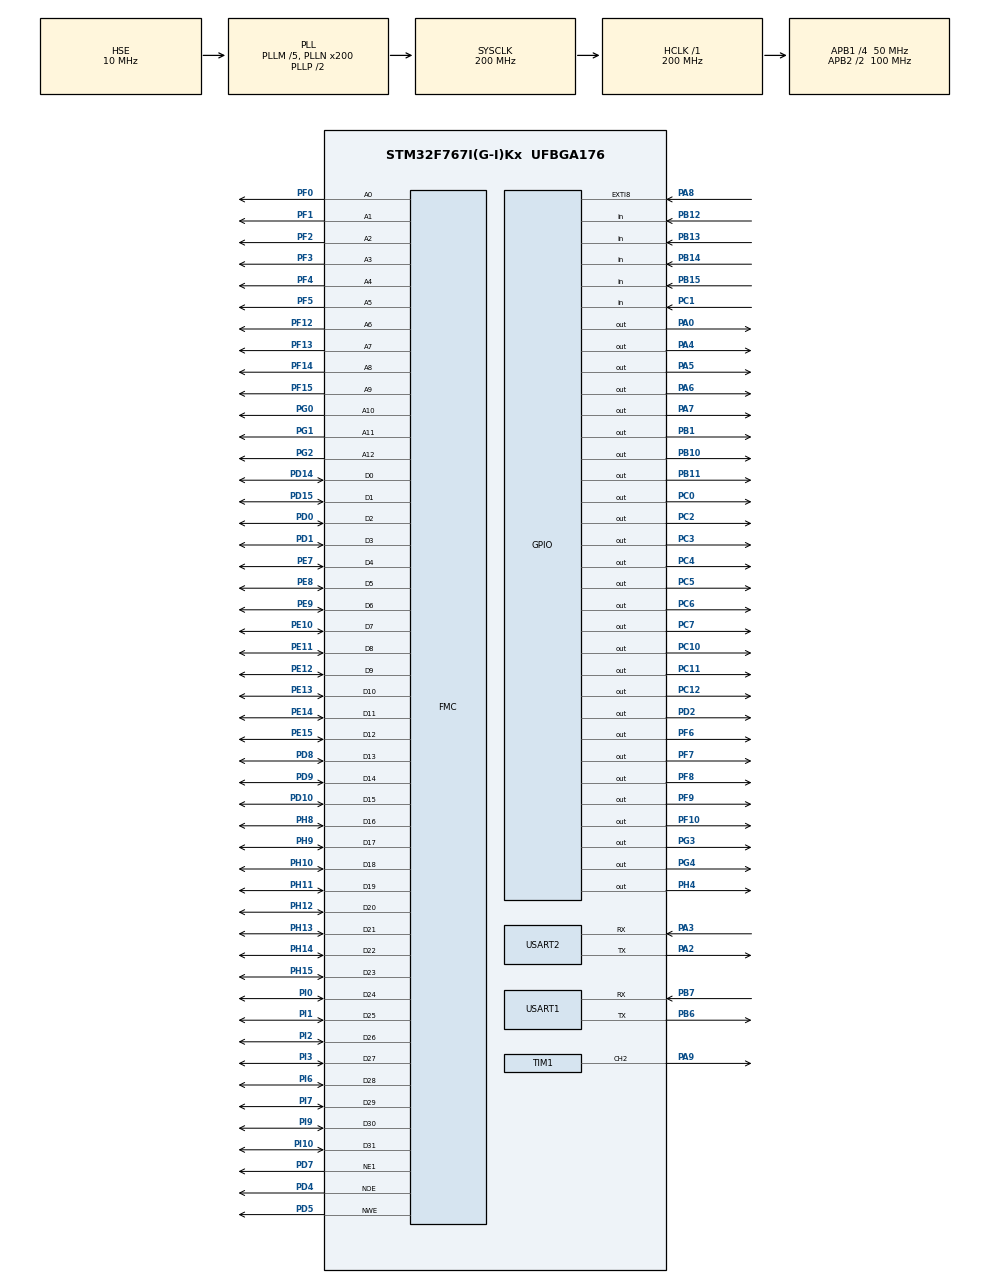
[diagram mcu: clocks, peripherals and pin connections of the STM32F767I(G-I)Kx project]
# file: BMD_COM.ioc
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CORTEX_M7.CPU_DCache=Disabled
CORTEX_M7.CPU_ICache=Enabled
Dma.Request0=USART2_RX
Dma.Request1=USART1_TX
Dma.Request2=USART1_RX
Dma.USART1_RX.2.Direction=DMA_PERIPH_TO_MEMORY
Dma.USART1_RX.2.FIFOMode=DMA_FIFOMODE_DISABLE
Dma.USART1_RX.2.Instance=DMA2_Stream2
Dma.USART1_RX.2.MemDataAlignment=DMA_MDATAALIGN_BYTE
Dma.USART1_RX.2.MemInc=DMA_MINC_ENABLE
Dma.USART1_RX.2.Mode=DMA_CIRCULAR
Dma.USART1_RX.2.PeriphDataAlignment=DMA_PDATAALIGN_BYTE
Dma.USART1_RX.2.PeriphInc=DMA_PINC_DISABLE
Dma.USART1_RX.2.Priority=DMA_PRIORITY_VERY_HIGH
Dma.USART1_TX.1.Direction=DMA_MEMORY_TO_PERIPH
Dma.USART1_TX.1.FIFOMode=DMA_FIFOMODE_DISABLE
Dma.USART1_TX.1.Instance=DMA2_Stream7
Dma.USART1_TX.1.MemDataAlignment=DMA_MDATAALIGN_BYTE
Dma.USART1_TX.1.MemInc=DMA_MINC_ENABLE
Dma.USART1_TX.1.Mode=DMA_NORMAL
Dma.USART1_TX.1.PeriphDataAlignment=DMA_PDATAALIGN_BYTE
Dma.USART1_TX.1.PeriphInc=DMA_PINC_DISABLE
Dma.USART1_TX.1.Priority=DMA_PRIORITY_LOW
Dma.USART2_RX.0.Direction=DMA_PERIPH_TO_MEMORY
Dma.USART2_RX.0.FIFOMode=DMA_FIFOMODE_DISABLE
Dma.USART2_RX.0.Instance=DMA1_Stream5
Dma.USART2_RX.0.MemDataAlignment=DMA_MDATAALIGN_BYTE
Dma.USART2_RX.0.MemInc=DMA_MINC_ENABLE
Dma.USART2_RX.0.Mode=DMA_CIRCULAR
Dma.USART2_RX.0.PeriphDataAlignment=DMA_PDATAALIGN_BYTE
Dma.USART2_RX.0.PeriphInc=DMA_PINC_DISABLE
Dma.USART2_RX.0.Priority=DMA_PRIORITY_HIGH
FMC.AddressSetupTime1=2
FMC.BusTurnAroundDuration1=2
FMC.DataSetupTime1=2
Mcu.Family=STM32F7
Mcu.Name=STM32F767I(G-I)Kx
Mcu.Package=UFBGA176
Mcu.UserConstants=USART1_BaudRate,921600;USART2_BaudRate,921600
NVIC.DMA1_Stream5_IRQn=true\:3\:0\:true\:true\:true\:5\:false\:true
NVIC.DMA2_Stream2_IRQn=true\:1\:0\:true\:true\:true\:6\:false\:true
NVIC.DMA2_Stream7_IRQn=true\:2\:0\:true\:true\:true\:2\:true\:true
NVIC.EXTI9_5_IRQn=true\:5\:0\:true\:true\:true\:3\:true\:true
NVIC.PriorityGroup=NVIC_PRIORITYGROUP_4
NVIC.TIM3_IRQn=true\:5\:0\:true\:true\:true\:4\:true\:true
NVIC.TIM6_DAC_IRQn=true\:4\:0\:true\:true\:true\:1\:true\:true
NVIC.USART1_IRQn=true\:0\:0\:true\:true\:true\:7\:true\:true
NVIC.USART2_IRQn=true\:6\:0\:true\:true\:true\:8\:true\:true
PA0/WKUP.GPIO_PuPd=GPIO_PULLUP
PA0/WKUP.Signal=GPIO_Output
PA2.GPIO_ModeDefaultPP=GPIO_MODE_AF_OD
PA2.Mode=Asynchronous
PA2.Signal=USART2_TX
PA3.GPIO_ModeDefaultPP=GPIO_MODE_AF_PP
PA3.Mode=Asynchronous
PA3.Signal=USART2_RX
PA4.GPIO_PuPd=GPIO_PULLUP
PA4.Signal=GPIO_Output
PA5.GPIO_PuPd=GPIO_PULLUP
PA5.Signal=GPIO_Output
PA6.GPIO_PuPd=GPIO_PULLUP
PA6.Signal=GPIO_Output
PA7.GPIO_PuPd=GPIO_PULLUP
PA7.Signal=GPIO_Output
PA8.GPIO_ModeDefaultEXTI=GPIO_MODE_IT_FALLING
PA8.GPIO_PuPd=GPIO_PULLUP
PA8.Signal=GPXTI8
PA9.Signal=S_TIM1_CH2
PB1.GPIO_PuPd=GPIO_PULLUP
PB1.Signal=GPIO_Output
PB10.GPIO_PuPd=GPIO_PULLUP
PB10.Signal=GPIO_Output
PB11.GPIO_PuPd=GPIO_PULLUP
PB11.Signal=GPIO_Output
PB12.GPIO_Mode=GPIO_MODE_INPUT
PB12.GPIO_PuPd=GPIO_PULLUP
PB12.Signal=GPIO_Input
PB13.GPIO_Mode=GPIO_MODE_INPUT
PB13.GPIO_PuPd=GPIO_PULLUP
PB13.Signal=GPIO_Input
PB14.GPIO_Mode=GPIO_MODE_INPUT
PB14.GPIO_PuPd=GPIO_PULLUP
PB14.Signal=GPIO_Input
PB15.GPIO_Mode=GPIO_MODE_INPUT
PB15.GPIO_PuPd=GPIO_PULLUP
PB15.Signal=GPIO_Input
PB6.Mode=Asynchronous
PB6.Signal=USART1_TX
PB7.Mode=Asynchronous
PB7.Signal=USART1_RX
PC0.GPIO_PuPd=GPIO_PULLUP
PC0.Signal=GPIO_Output
PC1.Signal=GPIO_Input
PC10.GPIO_PuPd=GPIO_PULLUP
PC10.Signal=GPIO_Output
PC11.GPIO_PuPd=GPIO_PULLUP
PC11.Signal=GPIO_Output
PC12.GPIO_PuPd=GPIO_PULLUP
PC12.Signal=GPIO_Output
PC2.GPIO_PuPd=GPIO_PULLUP
PC2.Signal=GPIO_Output
PC3.GPIO_PuPd=GPIO_PULLUP
PC3.Signal=GPIO_Output
PC4.GPIO_PuPd=GPIO_PULLUP
PC4.Signal=GPIO_Output
PC5.GPIO_PuPd=GPIO_PULLUP
PC5.Signal=GPIO_Output
PC6.GPIO_PuPd=GPIO_PULLUP
PC6.Signal=GPIO_Output
PC7.GPIO_PuPd=GPIO_PULLUP
PC7.Signal=GPIO_Output
PD0.Signal=FMC_D2_DA2
PD1.Signal=FMC_D3_DA3
PD10.Signal=FMC_D15_DA15
PD14.Signal=FMC_D0_DA0
PD15.Signal=FMC_D1_DA1
PD2.GPIO_PuPd=GPIO_PULLUP
PD2.Signal=GPIO_Output
PD4.Signal=FMC_NOE
PD5.Signal=FMC_NWE
PD7.Mode=NorPsramChipSelect1_1
PD7.Signal=FMC_NE1
PD8.Signal=FMC_D13_DA13
PD9.Signal=FMC_D14_DA14
PE10.Signal=FMC_D7_DA7
PE11.Signal=FMC_D8_DA8
PE12.Signal=FMC_D9_DA9
PE13.Signal=FMC_D10_DA10
PE14.Signal=FMC_D11_DA11
PE15.Signal=FMC_D12_DA12
PE7.Signal=FMC_D4_DA4
PE8.Signal=FMC_D5_DA5
PE9.Signal=FMC_D6_DA6
PF0.Signal=FMC_A0
PF1.Signal=FMC_A1
PF10.GPIO_PuPd=GPIO_PULLUP
PF10.Signal=GPIO_Output
PF12.Signal=FMC_A6
PF13.Signal=FMC_A7
PF14.Signal=FMC_A8
PF15.Signal=FMC_A9
PF2.Signal=FMC_A2
PF3.Signal=FMC_A3
PF4.Signal=FMC_A4
PF5.Signal=FMC_A5
PF6.GPIO_PuPd=GPIO_PULLUP
PF6.Signal=GPIO_Output
PF7.GPIO_PuPd=GPIO_PULLUP
PF7.Signal=GPIO_Output
PF8.GPIO_PuPd=GPIO_PULLUP
PF8.Signal=GPIO_Output
PF9.GPIO_PuPd=GPIO_PULLUP
PF9.Signal=GPIO_Output
PG0.Signal=FMC_A10
PG1.Signal=FMC_A11
PG2.Signal=FMC_A12
PG3.GPIO_PuPd=GPIO_NOPULL
PG3.GPIO_Speed=GPIO_SPEED_FREQ_VERY_HIGH
PG3.PinState=GPIO_PIN_SET
PG3.Signal=GPIO_Output
PG4.GPIO_PuPd=GPIO_NOPULL
PG4.GPIO_Speed=GPIO_SPEED_FREQ_VERY_HIGH
PG4.PinState=GPIO_PIN_SET
PG4.Signal=GPIO_Output
PH0/OSC_IN.Mode=HSE-External-Clock-Source
PH0/OSC_IN.Signal=RCC_OSC_IN
PH1/OSC_OUT.Mode=HSE-External-Clock-Source
PH1/OSC_OUT.Signal=RCC_OSC_OUT
PH10.Signal=FMC_D18
PH11.Signal=FMC_D19
PH12.Signal=FMC_D20
PH13.Signal=FMC_D21
PH14.Signal=FMC_D22
PH15.Signal=FMC_D23
PH4.GPIO_PuPd=GPIO_PULLUP
PH4.Signal=GPIO_Output
PH8.Signal=FMC_D16
PH9.Signal=FMC_D17
PI0.Signal=FMC_D24
PI1.Signal=FMC_D25
PI10.Signal=FMC_D31
PI2.Signal=FMC_D26
PI3.Signal=FMC_D27
PI6.Signal=FMC_D28
PI7.Signal=FMC_D29
PI9.Signal=FMC_D30
ProjectManager.HeapSize=0x200
ProjectManager.StackSize=0x400
ProjectManager.TargetToolchain=MDK-ARM V5
RCC.AHBFreq_Value=200000000
RCC.APB1CLKDivider=RCC_HCLK_DIV4
RCC.APB1Freq_Value=50000000
RCC.APB1TimFreq_Value=100000000
RCC.APB2CLKDivider=RCC_HCLK_DIV2
RCC.APB2Freq_Value=100000000
RCC.APB2TimFreq_Value=200000000
RCC.CortexFreq_Value=200000000
RCC.HCLKFreq_Value=200000000
RCC.HSE_VALUE=10000000
RCC.HSI_VALUE=16000000
RCC.LSE_VALUE=32768
RCC.PLLM=5
RCC.PLLN=200
RCC.PLLSourceVirtual=RCC_PLLSOURCE_HSE
RCC.SYSCLKFreq_VALUE=200000000
RCC.SYSCLKSource=RCC_SYSCLKSOURCE_PLLCLK
RCC.USBFreq_Value=200000000
RCC.VCOOutputFreq_Value=400000000
SH.FMC_A0.0=FMC_A0,13b-a1
SH.FMC_A1.0=FMC_A1,13b-a1
SH.FMC_A10.0=FMC_A10,13b-a1
SH.FMC_A11.0=FMC_A11,13b-a1
SH.FMC_A12.0=FMC_A12,13b-a1
SH.FMC_A2.0=FMC_A2,13b-a1
SH.FMC_A3.0=FMC_A3,13b-a1
SH.FMC_A4.0=FMC_A4,13b-a1
SH.FMC_A5.0=FMC_A5,13b-a1
SH.FMC_A6.0=FMC_A6,13b-a1
SH.FMC_A7.0=FMC_A7,13b-a1
SH.FMC_A8.0=FMC_A8,13b-a1
SH.FMC_A9.0=FMC_A9,13b-a1
SH.FMC_D0_DA0.0=FMC_D0,32b-d1
SH.FMC_D10_DA10.0=FMC_D10,32b-d1
SH.FMC_D11_DA11.0=FMC_D11,32b-d1
SH.FMC_D12_DA12.0=FMC_D12,32b-d1
SH.FMC_D13_DA13.0=FMC_D13,32b-d1
SH.FMC_D14_DA14.0=FMC_D14,32b-d1
SH.FMC_D15_DA15.0=FMC_D15,32b-d1
SH.FMC_D16.0=FMC_D16,32b-d1
SH.FMC_D17.0=FMC_D17,32b-d1
SH.FMC_D18.0=FMC_D18,32b-d1
SH.FMC_D19.0=FMC_D19,32b-d1
SH.FMC_D1_DA1.0=FMC_D1,32b-d1
SH.FMC_D20.0=FMC_D20,32b-d1
SH.FMC_D21.0=FMC_D21,32b-d1
SH.FMC_D22.0=FMC_D22,32b-d1
SH.FMC_D23.0=FMC_D23,32b-d1
SH.FMC_D24.0=FMC_D24,32b-d1
SH.FMC_D25.0=FMC_D25,32b-d1
SH.FMC_D26.0=FMC_D26,32b-d1
SH.FMC_D27.0=FMC_D27,32b-d1
SH.FMC_D28.0=FMC_D28,32b-d1
SH.FMC_D29.0=FMC_D29,32b-d1
SH.FMC_D2_DA2.0=FMC_D2,32b-d1
SH.FMC_D30.0=FMC_D30,32b-d1
SH.FMC_D31.0=FMC_D31,32b-d1
SH.FMC_D3_DA3.0=FMC_D3,32b-d1
SH.FMC_D4_DA4.0=FMC_D4,32b-d1
SH.FMC_D5_DA5.0=FMC_D5,32b-d1
SH.FMC_D6_DA6.0=FMC_D6,32b-d1
SH.FMC_D7_DA7.0=FMC_D7,32b-d1
SH.FMC_D8_DA8.0=FMC_D8,32b-d1
SH.FMC_D9_DA9.0=FMC_D9,32b-d1
SH.FMC_NOE.0=FMC_NOE,Sram1
SH.FMC_NWE.0=FMC_NWE,Sram1
SH.S_TIM1_CH2.0=TIM1_CH2,PWM Generation2 CH2
TIM1.Channel-PWM\ Generation2\ CH2=TIM_CHANNEL_2
TIM1.Period=9
TIM1.Prescaler=1
TIM1.Pulse-PWM\ Generation2\ CH2=5
TIM3.Period=9
TIM3.Prescaler=99
TIM5.Period=0xFFFFFFFF
TIM5.Prescaler=99
TIM6.Period=99
TIM6.Prescaler=999
USART1.BaudRate=USART1_BaudRate
USART1.OverSampling=UART_OVERSAMPLING_8
USART1.VirtualMode-Asynchronous=VM_ASYNC
USART1.WordLength=WORDLENGTH_8B
USART2.BaudRate=USART2_BaudRate
USART2.OverSampling=UART_OVERSAMPLING_8
USART2.VirtualMode-Asynchronous=VM_ASYNC
USART2.WordLength=WORDLENGTH_8B
VP_TIM1_VS_ClockSourceINT.Mode=Internal
VP_TIM3_VS_ClockSourceINT.Mode=Internal
VP_TIM5_VS_ClockSourceINT.Mode=Internal
VP_TIM6_VS_ClockSourceINT.Mode=Enable_Timer
board=BMD_COM

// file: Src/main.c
/* USER CODE BEGIN Header */
/**
  ******************************************************************************
  * @file           : main.c
  * @brief          : Main program body
  ******************************************************************************
  * @attention
  *
  * <h2><center>&copy; Copyright (c) 2019 STMicroelectronics.
  * All rights reserved.</center></h2>
  *
  * This software component is licensed by ST under BSD 3-Clause license,
  * the "License"; You may not use this file except in compliance with the
  * License. You may obtain a copy of the License at:
  *                        opensource.org/licenses/BSD-3-Clause
  *
  ******************************************************************************
  */
/* USER CODE END Header */

#include "main.h"
#include "dma.h"
#include "tim.h"
#include "usart.h"
#include "gpio.h"
#include "fmc.h"

/* USER CODE BEGIN Includes */
#include "GlobalDefine.h"
/* USER CODE END Includes */

/* USER CODE BEGIN PV */
/* Private variables ---------------------------------------------------------*/

/* USER CODE END PV */

void SystemClock_Config(void);
static void MX_NVIC_Init(void);
/* USER CODE BEGIN PFP */
/* Private function prototypes -----------------------------------------------*/

/* USER CODE END PFP */

/* USER CODE BEGIN 0 */
void MPU_Config(void)
{
  MPU_Region_InitTypeDef MPU_InitStruct;

  /* Disable the MPU */
  HAL_MPU_Disable();

  /* Configure the MPU attributes as WT for SRAM */
  MPU_InitStruct.Enable = MPU_REGION_ENABLE;
  MPU_InitStruct.BaseAddress = 0x60000000;
  MPU_InitStruct.Size = MPU_REGION_SIZE_64MB;
  MPU_InitStruct.AccessPermission = MPU_REGION_FULL_ACCESS;
  MPU_InitStruct.IsBufferable = MPU_ACCESS_NOT_BUFFERABLE;
  MPU_InitStruct.IsCacheable = MPU_ACCESS_CACHEABLE;
  MPU_InitStruct.IsShareable = MPU_ACCESS_SHAREABLE;
  MPU_InitStruct.Number = MPU_REGION_NUMBER1;
  MPU_InitStruct.TypeExtField = MPU_TEX_LEVEL0;
  MPU_InitStruct.SubRegionDisable = 0x00;
  MPU_InitStruct.DisableExec = MPU_INSTRUCTION_ACCESS_ENABLE;

  HAL_MPU_ConfigRegion(&MPU_InitStruct);

  /* Enable the MPU */
  HAL_MPU_Enable(MPU_PRIVILEGED_DEFAULT);
}
/* USER CODE END 0 */

int main(void)
{

  /* Enable I-Cache---------------------------------------------------------*/
  SCB_EnableICache();

  /* MCU Configuration--------------------------------------------------------*/

  /* Reset of all peripherals, Initializes the Flash interface and the Systick. */
  HAL_Init();

  /* USER CODE BEGIN Init */
  MPU_Config();
  /* USER CODE END Init */

  /* Configure the system clock */
  SystemClock_Config();

  /* USER CODE BEGIN SysInit */
  GlobalDefine_Init();
  DataStorage_Init();
  DataLink_Init();
	ExtDevCon_Init();
  Datastorage_Read();
  DevCompensation_Init();
  Config_Init();
  /* USER CODE END SysInit */

  /* Initialize all configured peripherals */
  MX_GPIO_Init();
  MX_DMA_Init();
  MX_TIM1_Init();
  MX_TIM5_Init();
  MX_TIM6_Init();
  MX_USART1_UART_Init();
  MX_USART2_UART_Init();
  MX_FMC_Init();
  MX_TIM3_Init();

  /* Initialize interrupts */
  MX_NVIC_Init();
  /* USER CODE BEGIN 2 */
  TaskSequence_Init();
  System_Init();

  /* USER CODE END 2 */

  /* Infinite loop */
  while (1)
  {

    /* USER CODE BEGIN 3 */
    Task_Run_Sequence();
  }
  /* USER CODE END 3 */
}

void SystemClock_Config(void)
{
  RCC_OscInitTypeDef RCC_OscInitStruct = {0};
  RCC_ClkInitTypeDef RCC_ClkInitStruct = {0};
  RCC_PeriphCLKInitTypeDef PeriphClkInitStruct = {0};

  /** Configure the main internal regulator output voltage
  */
  __HAL_RCC_PWR_CLK_ENABLE();
  __HAL_PWR_VOLTAGESCALING_CONFIG(PWR_REGULATOR_VOLTAGE_SCALE1);
  /** Initializes the CPU, AHB and APB busses clocks
  */
  RCC_OscInitStruct.OscillatorType = RCC_OSCILLATORTYPE_HSE;
  RCC_OscInitStruct.HSEState = RCC_HSE_BYPASS;
  RCC_OscInitStruct.PLL.PLLState = RCC_PLL_ON;
  RCC_OscInitStruct.PLL.PLLSource = RCC_PLLSOURCE_HSE;
  RCC_OscInitStruct.PLL.PLLM = 5;
  RCC_OscInitStruct.PLL.PLLN = 200;
  RCC_OscInitStruct.PLL.PLLP = RCC_PLLP_DIV2;
  RCC_OscInitStruct.PLL.PLLQ = 2;
  if (HAL_RCC_OscConfig(&RCC_OscInitStruct) != HAL_OK)
  {
    Error_Handler();
  }
  /** Activate the Over-Drive mode
  */
  if (HAL_PWREx_EnableOverDrive() != HAL_OK)
  {
    Error_Handler();
  }
  /** Initializes the CPU, AHB and APB busses clocks
  */
  RCC_ClkInitStruct.ClockType = RCC_CLOCKTYPE_HCLK|RCC_CLOCKTYPE_SYSCLK
                              |RCC_CLOCKTYPE_PCLK1|RCC_CLOCKTYPE_PCLK2;
  RCC_ClkInitStruct.SYSCLKSource = RCC_SYSCLKSOURCE_PLLCLK;
  RCC_ClkInitStruct.AHBCLKDivider = RCC_SYSCLK_DIV1;
  RCC_ClkInitStruct.APB1CLKDivider = RCC_HCLK_DIV4;
  RCC_ClkInitStruct.APB2CLKDivider = RCC_HCLK_DIV2;

  if (HAL_RCC_ClockConfig(&RCC_ClkInitStruct, FLASH_LATENCY_6) != HAL_OK)
  {
    Error_Handler();
  }
  PeriphClkInitStruct.PeriphClockSelection = RCC_PERIPHCLK_USART1|RCC_PERIPHCLK_USART2;
  PeriphClkInitStruct.Usart1ClockSelection = RCC_USART1CLKSOURCE_PCLK2;
  PeriphClkInitStruct.Usart2ClockSelection = RCC_USART2CLKSOURCE_PCLK1;
  if (HAL_RCCEx_PeriphCLKConfig(&PeriphClkInitStruct) != HAL_OK)
  {
    Error_Handler();
  }
}

/**
  * @brief NVIC Configuration.
  * @retval None
  */
static void MX_NVIC_Init(void)
{
  /* TIM6_DAC_IRQn interrupt configuration */
  HAL_NVIC_SetPriority(TIM6_DAC_IRQn, 4, 0);
  HAL_NVIC_EnableIRQ(TIM6_DAC_IRQn);
  /* DMA2_Stream7_IRQn interrupt configuration */
  HAL_NVIC_SetPriority(DMA2_Stream7_IRQn, 2, 0);
  HAL_NVIC_EnableIRQ(DMA2_Stream7_IRQn);
  /* EXTI9_5_IRQn interrupt configuration */
  HAL_NVIC_SetPriority(EXTI9_5_IRQn, 5, 0);
  HAL_NVIC_EnableIRQ(EXTI9_5_IRQn);
  /* TIM3_IRQn interrupt configuration */
  HAL_NVIC_SetPriority(TIM3_IRQn, 5, 0);
  HAL_NVIC_EnableIRQ(TIM3_IRQn);
  /* DMA1_Stream5_IRQn interrupt configuration */
  HAL_NVIC_SetPriority(DMA1_Stream5_IRQn, 3, 0);
  HAL_NVIC_EnableIRQ(DMA1_Stream5_IRQn);
  /* DMA2_Stream2_IRQn interrupt configuration */
  HAL_NVIC_SetPriority(DMA2_Stream2_IRQn, 1, 0);
  HAL_NVIC_EnableIRQ(DMA2_Stream2_IRQn);
  /* USART1_IRQn interrupt configuration */
  HAL_NVIC_SetPriority(USART1_IRQn, 0, 0);
  HAL_NVIC_EnableIRQ(USART1_IRQn);
  /* USART2_IRQn interrupt configuration */
  HAL_NVIC_SetPriority(USART2_IRQn, 6, 0);
  HAL_NVIC_EnableIRQ(USART2_IRQn);
}

void Error_Handler(void)
{
  while(1)
  {
  }
}

/************************ (C) COPYRIGHT STMicroelectronics *****END OF FILE****/
